# ATxmega32E5 device description
Architecture: AVR8_XMEGA; Family: AVR XMEGA
Registers are 8-bit, access not given, no defined reset value unless marked. A register's access mark holds for its fields unless they carry their own. Offsets are from the block's base; [hi:lo] are bit positions; {n}, {i} and the like mark numbered series.

## CRC — Cyclic Redundancy Checker
Instances: CRC 0x0D0
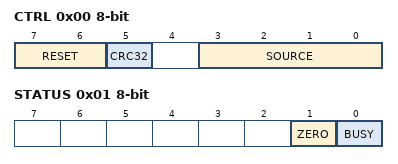
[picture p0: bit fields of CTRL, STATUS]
0x00 CTRL — Control Register
  [7:6] RESET
    0=NO (No Reset); 2=Reset CRC with CHECKSUM to all zeros; 3=Reset CRC with CHECKSUM to all ones
  [5] CRC32 — CRC Mode
  [3:0] SOURCE — Input Source
    0=DISABLE (Disabled); 1=IO (I/O Interface); 2=FLASH; {v}=DMAC{v-4} (DMAC Channel {v-4}) (v=4..7)
0x01 STATUS
  [1] ZERO — Zero detection
  [0] BUSY
0x03 DATAIN — Data Input
{0x4+i} CHECKSUM{i} (i=0..3) — Checksum byte {i}

## EVSYS — Event System
Instances: EVSYS 0x0180
{0x0+i} CH{i}MUX (i=0..7) — Event Channel {i} Multiplexer
  [7:0] CHMUX
    0=OFF; 8=RTC_OVF (RTC Overflow); 9=RTC_CMP (RTC Compare Match); 16=ACA_CH0 (Analog Comparator A Channel 0); 17=ACA_CH1 (Analog Comparator A Channel 1); 18=ACA_WIN (Analog Comparator A Window); 32=ADCA_CH0 (ADC A Channel 0); {v}=PORTA_PIN{v-80} (v=80..87); {v}=PORTC_PIN{v-96} (v=96..103); {v}=PORTD_PIN{v-104} (v=104..111); 128=PRESCALER_1 (Prescaler, divide by 1); 129=PRESCALER_2 (Prescaler, divide by 2); 130=PRESCALER_4 (Prescaler, divide by 4); 131=PRESCALER_8 (Prescaler, divide by 8); 132=PRESCALER_16 (Prescaler, divide by 16); 133=PRESCALER_32 (Prescaler, divide by 32); 134=PRESCALER_64 (Prescaler, divide by 64); 135=PRESCALER_128 (Prescaler, divide by 128); 136=PRESCALER_256 (Prescaler, divide by 256); 137=PRESCALER_512 (Prescaler, divide by 512); 138=PRESCALER_1024 (Prescaler, divide by 1024); 139=PRESCALER_2048 (Prescaler, divide by 2048); 140=PRESCALER_4096 (Prescaler, divide by 4096); 141=PRESCALER_8192 (Prescaler, divide by 8192); 142=PRESCALER_16384 (Prescaler, divide by 16384); 143=PRESCALER_32768 (Prescaler, divide by 32768); 176=XCL_UNF0 (XCL BTC0 underflow); 177=XCL_UNF1 (XCL BTC1 underflow); 178=XCL_CC0 (XCL BTC0 capture or compare); 179=XCL_CC1 (XCL BTC1 capture or compare); 180=XCL_PEC0 (XCL PEC0 restart); 181=XCL_PEC1 (XCL PEC1 restart); 182=XCL_LUT0 (XCL LUT0 output); 183=XCL_LUT1 (XCL LUT1 output); 192=TCC4_OVF (Timer/Counter C4 Overflow); 193=TCC4_ERR (Timer/Counter C4 Error); 196=TCC4_CCA (Timer/Counter C4 Compare or Capture A); 197=TCC4_CCB (Timer/Counter C4 Compare or Capture B); 198=TCC4_CCC (Timer/Counter C4 Compare or Capture C); 199=TCC4_CCD (Timer/Counter C4 Compare or Capture D); 200=TCC5_OVF (Timer/Counter C5 Overflow); 201=TCC5_ERR (Timer/Counter C5 Error); 204=TCC5_CCA (Timer/Counter C5 Compare or Capture A); 205=TCC5_CCB (Timer/Counter C5 Compare or Capture B); 216=TCD5_OVF (Timer/Counter D5 Overflow); 217=TCD5_ERR (Timer/Counter D5 Error); 220=TCD5_CCA (Timer/Counter D5 Compare or Capture A); 221=TCD5_CCB (Timer/Counter D5 Compare or Capture B)
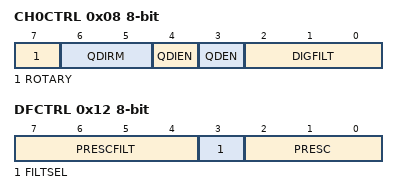
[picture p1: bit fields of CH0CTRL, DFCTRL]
0x08 CH0CTRL — Channel 0 Control Register
  [7] ROTARY — Rotary Decoder Enable
  [6:5] QDIRM — Quadrature Decoder Index Recognition Mode
    0=QDPH0 = 0, QDPH90 = 0; 1=QDPH0 = 0, QDPH90 = 1; 2=QDPH0 = 1, QDPH90 = 0; 3=QDPH0 = 1, QDPH90 = 1
  [4] QDIEN — Quadrature Decoder Index Enable
  [3] QDEN — Quadrature Decoder Enable
  [2:0] DIGFILT — Digital Filter
    0=1SAMPLE; {v}={v+1}SAMPLES (v=1..7)
{0x8+i} CH{i}CTRL (i=1..7) — Channel {i} Control Register
  [2:0] DIGFILT — Digital Filter
    0=1SAMPLE; {v}={v+1}SAMPLES (v=1..7)
0x10 STROBE — Event Strobe
0x11 DATA — Event Data
0x12 DFCTRL — Digital Filter Control Register
  [7:4] PRESCFILT — Prescaler Filter
    1=CH04 (Enable prescaler filter for either channel 0 or 4); 2=CH15 (Enable prescaler filter for either channel 1 or 5); 4=CH26 (Enable prescaler filter for either channel 2 or 6); 8=CH37 (Enable prescaler filter for either channel 3 or 7)
  [3] FILTSEL — Prescaler Filter Select
  [2:0] PRESC — Prescaler
    0=CLKPER_8 (CLKPER, divide by 8); 1=CLKPER_64 (CLKPER, divide by 64); 2=CLKPER_512 (CLKPER, divide by 512); 3=CLKPER_4096 (CLKPER, divide by 4096); 4=CLKPER_32768 (CLKPER, divide by 32768)
